# STM32C031 register map
File version: 1.4
CPU: CM0 r0p0, little endian, MPU, FPU, 4 interrupt priority bits
Registers are 32-bit, read-write, reset 0x0 unless marked. A register's access mark holds for its fields unless they carry their own. Offsets are from the block's base; [hi:lo] are bit positions.

## RTC — RTC register block
Base 0x40002800
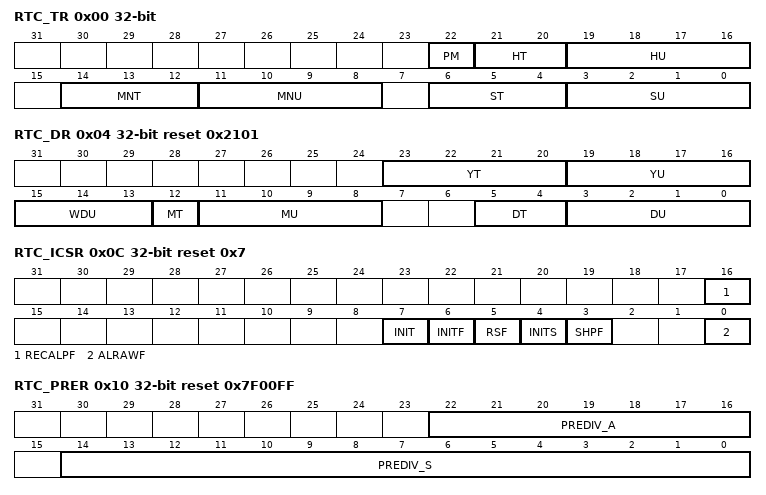
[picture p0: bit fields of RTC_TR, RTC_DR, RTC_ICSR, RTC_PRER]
0x00 RTC_TR — RTC time register
  [22] PM — AM/PM notation
    0=AM or 24-hour format; 1=PM
  [21:20] HT — Hour tens in BCD format
  [19:16] HU — Hour units in BCD format
  [14:12] MNT — Minute tens in BCD format
  [11:8] MNU — Minute units in BCD format
  [6:4] ST — Second tens in BCD format
  [3:0] SU — Second units in BCD format
0x04 RTC_DR reset 0x2101 — RTC date register
  [23:20] YT — Year tens in BCD format
  [19:16] YU — Year units in BCD format
  [15:13] WDU — Week day units ...
    0=forbidden; 1=Monday; 7=Sunday
  [12] MT — Month tens in BCD format
  [11:8] MU — Month units in BCD format
  [5:4] DT — Date tens in BCD format
  [3:0] DU — Date units in BCD format
0x08 RTC_SSR ro — RTC sub second register
  [15:0] SS — Sub second value SS[15:0] is the value in the synchronous prescaler counter. The fraction of a second is given by the formula below: Second fraction = (PREDIV_S - SS) / (PREDIV_S + 1) Note: SS can be larger than PREDIV_S only after a shift operation. In that case, the correct time/date is one second less than as indicated by RTC_TR/RTC_DR.
0x0C RTC_ICSR access per field reset 0x7 — RTC initialization control and status register
  [16] RECALPF ro — Recalibration pending Flag The RECALPF status flag is automatically set to 1 when software writes to the RTC_CALR register, indicating that the RTC_CALR register is blocked. When the new calibration settings are taken into account, this bit returns to 0. Refer to .
  [7] INIT rw — Initialization mode
    0=Free running mode; 1=Initialization mode used to program time and date register (RTC_TR and RTC_DR), and prescaler register (RTC_PRER). Counters are stopped and start counting from the new value when INIT is reset.
  [6] INITF ro — Initialization flag When this bit is set to 1, the RTC is in initialization state, and the time, date and prescaler registers can be updated.
    0=Calendar registers update is not allowed; 1=Calendar registers update is allowed
  [5] RSF rw — Registers synchronization flag This bit is set by hardware each time the calendar registers are copied into the shadow registers (RTC_SSR, RTC_TR and RTC_DR). This bit is cleared by hardware in initialization mode, while a shift operation is pending (SHPF = 1), or when in bypass shadow register mode (BYPSHAD = 1). This bit can also be cleared by software. It is cleared either by software or by hardware in initialization mode.
    0=Calendar shadow registers not yet synchronized; 1=Calendar shadow registers synchronized
  [4] INITS ro — Initialization status flag This bit is set by hardware when the calendar year field is different from 0 (Power-on reset state).
    0=Calendar has not been initialized; 1=Calendar has been initialized
  [3] SHPF ro — Shift operation pending This flag is set by hardware as soon as a shift operation is initiated by a write to the RTC_SHIFTR register. It is cleared by hardware when the corresponding shift operation has been executed. Writing to the SHPF bit has no effect.
    0=No shift operation is pending; 1=A shift operation is pending
  [0] ALRAWF ro — Alarm A write flag This bit is set by hardware when alarm A values can be changed, after the ALRAE bit has been set to 0 in RTC_CR. It is cleared by hardware in initialization mode.
    0=Alarm A update not allowed; 1=Alarm A update allowed
0x10 RTC_PRER reset 0x7F00FF — RTC prescaler register
  [22:16] PREDIV_A — Asynchronous prescaler factor This is the asynchronous division factor: ck_apre frequency = RTCCLK frequency/(PREDIV_A+1)
  [14:0] PREDIV_S — Synchronous prescaler factor This is the synchronous division factor: ck_spre frequency = ck_apre frequency/(PREDIV_S+1)
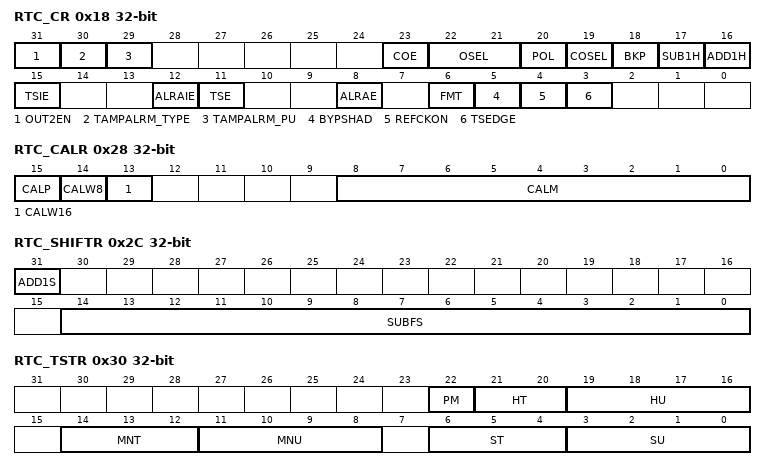
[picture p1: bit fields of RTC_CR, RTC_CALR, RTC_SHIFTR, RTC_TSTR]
0x18 RTC_CR access per field — RTC control register
  [31] OUT2EN rw — RTC_OUT2 output enable Setting this bit allows to remap the RTC outputs on RTC_OUT2 as follows: OUT2EN = 0: RTC output 2 disable If OSEL different of 00 or TAMPOE = 1: TAMPALRM is output on RTC_OUT1 If OSEL = 00 and TAMPOE = 0 and COE = 1: CALIB is output on RTC_OUT1 OUT2EN = 1: RTC output 2 enable If (OSEL different of 00 or TAMPOE = 1) and COE = 0: TAMPALRM is output on RTC_OUT2 If OSEL = 00 and TAMPOE = 0 and COE = 1: CALIB is output on RTC_OUT2 If (OSELdifferent of 00 or TAMPOE = 1) and COE = 1: CALIB is output on RTC_OUT2 and TAMPALRM is output on RTC_OUT1.
  [30] TAMPALRM_TYPE rw — TAMPALRM output type
    0=TAMPALRM is push-pull output; 1=TAMPALRM is open-drain output
  [29] TAMPALRM_PU rw — TAMPALRM pull-up enable
    0=No pull-up is applied on TAMPALRM output; 1=A pull-up is applied on TAMPALRM output
  [23] COE rw — Calibration output enable This bit enables the CALIB output
    0=Calibration output disabled; 1=Calibration output enabled
  [22:21] OSEL rw — Output selection These bits are used to select the flag to be routed to TAMPALRM output.
    0=Output disabled; 1=Alarm A output enabled
  [20] POL rw — Output polarity This bit is used to configure the polarity of TAMPALRM output.
    0=The pin is high when ALRAF is asserted (depending on OSEL[1:0]); 1=The pin is low when ALRAF is asserted (depending on OSEL[1:0])
  [19] COSEL rw — Calibration output selection When COE = 1, this bit selects which signal is output on CALIB. These frequencies are valid for RTCCLK at 32.768 kHz and prescalers at their default values (PREDIV_A = 127 and PREDIV_S = 255). Refer to .
    0=Calibration output is 512 Hz; 1=Calibration output is 1 Hz
  [18] BKP rw — Backup This bit can be written by the user to memorize whether the daylight saving time change has been performed or not.
  [17] SUB1H wo — Subtract 1 hour (winter time change) When this bit is set outside initialization mode, 1 hour is subtracted to the calendar time if the current hour is not 0. This bit is always read as 0. Setting this bit has no effect when current hour is 0.
    0=No effect; 1=Subtracts 1 hour to the current time. This can be used for winter time change.
  [16] ADD1H wo — Add 1 hour (summer time change) When this bit is set outside initialization mode, 1 hour is added to the calendar time. This bit is always read as 0.
    0=No effect; 1=Adds 1 hour to the current time. This can be used for summer time change
  [15] TSIE rw — Timestamp interrupt enable
    0=Timestamp interrupt disable; 1=Timestamp interrupt enable
  [12] ALRAIE rw — Alarm A interrupt enable
    0=Alarm A interrupt disabled; 1=Alarm A interrupt enabled
  [11] TSE rw — timestamp enable
    0=timestamp disable; 1=timestamp enable
  [8] ALRAE rw — Alarm A enable
    0=Alarm A disabled; 1=Alarm A enabled
  [6] FMT rw — Hour format
    0=24 hour/day format; 1=AM/PM hour format
  [5] BYPSHAD rw — Bypass the shadow registers Note: If the frequency of the APB1 clock is less than seven times the frequency of RTCCLK, BYPSHAD must be set to 1.
    0=Calendar values (when reading from RTC_SSR, RTC_TR, and RTC_DR) are taken from the shadow registers, which are updated once every two RTCCLK cycles; 1=Calendar values (when reading from RTC_SSR, RTC_TR, and RTC_DR) are taken directly from the calendar counters
  [4] REFCKON rw — RTC_REFIN reference clock detection enable (50 or 60 Hz) Note: PREDIV_S must be 0x00FF.
    0=RTC_REFIN detection disabled; 1=RTC_REFIN detection enabled
  [3] TSEDGE rw — Timestamp event active edge TSE must be reset when TSEDGE is changed to avoid unwanted TSF setting.
    0=RTC_TS input rising edge generates a timestamp event; 1=RTC_TS input falling edge generates a timestamp event
0x24 RTC_WPR wo — RTC write protection register
  [7:0] KEY — Write protection key This byte is written by software. Reading this byte always returns 0x00. Refer to for a description of how to unlock RTC register write protection.
0x28 RTC_CALR — RTC calibration register
  [15] CALP — Increase frequency of RTC by 488.5 ppm This feature is intended to be used in conjunction with CALM, which lowers the frequency of the calendar with a fine resolution. if the input frequency is 32768 Hz, the number of RTCCLK pulses added during a 32-second window is calculated as follows: (512 CALP) - CALM. Refer to .
    0=No RTCCLK pulses are added; 1=One RTCCLK pulse is effectively inserted every 211 pulses (frequency increased by 488.5 ppm)
  [14] CALW8 — Use an 8-second calibration cycle period When CALW8 is set to 1, the 8-second calibration cycle period is selected. Note: CALM[1:0] are stuck at 00 when CALW8 = 1. Refer to digital calibration.
  [13] CALW16 — Use a 16-second calibration cycle period When CALW16 is set to 1, the 16-second calibration cycle period is selected. This bit must not be set to 1 if CALW8 = 1. Note: CALM[0] is stuck at 0 when CALW16 = 1. Refer to calibration.
  [8:0] CALM — Calibration minus The frequency of the calendar is reduced by masking CALM out of 220 RTCCLK pulses (32 seconds if the input frequency is 32768 Hz). This decreases the frequency of the calendar with a resolution of 0.9537 ppm. To increase the frequency of the calendar, this feature should be used in conjunction with CALP. See .
0x2C RTC_SHIFTR wo — RTC shift control register
  [31] ADD1S — Add one second This bit is write only and is always read as zero. Writing to this bit has no effect when a shift operation is pending (when SHPF = 1, in RTC_ICSR). This function is intended to be used with SUBFS (see description below) in order to effectively add a fraction of a second to the clock in an atomic operation.
    0=No effect; 1=Add one second to the clock/calendar
  [14:0] SUBFS — Subtract a fraction of a second These bits are write only and is always read as zero. Writing to this bit has no effect when a shift operation is pending (when SHPF = 1, in RTC_ICSR). The value which is written to SUBFS is added to the synchronous prescaler counter. Since this counter counts down, this operation effectively subtracts from (delays) the clock by: Delay (seconds) = SUBFS / (PREDIV_S + 1) A fraction of a second can effectively be added to the clock (advancing the clock) when the ADD1S function is used in conjunction with SUBFS, effectively advancing the clock by: Advance (seconds) = (1 - (SUBFS / (PREDIV_S + 1))). Note: Writing to SUBFS causes RSF to be cleared. Software can then wait until RSF = 1 to be sure that the shadow registers have been updated with the shifted time.
0x30 RTC_TSTR ro — RTC timestamp time register
  [22] PM — AM/PM notation
    0=AM or 24-hour format; 1=PM
  [21:20] HT — Hour tens in BCD format.
  [19:16] HU — Hour units in BCD format.
  [14:12] MNT — Minute tens in BCD format.
  [11:8] MNU — Minute units in BCD format.
  [6:4] ST — Second tens in BCD format.
  [3:0] SU — Second units in BCD format.
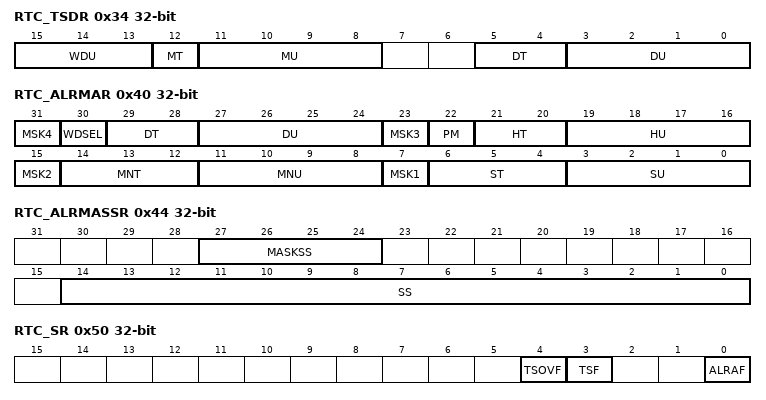
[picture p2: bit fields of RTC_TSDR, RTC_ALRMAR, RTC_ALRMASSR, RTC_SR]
0x34 RTC_TSDR ro — RTC timestamp date register
  [15:13] WDU — Week day units
  [12] MT — Month tens in BCD format
  [11:8] MU — Month units in BCD format
  [5:4] DT — Date tens in BCD format
  [3:0] DU — Date units in BCD format
0x38 RTC_TSSSR ro — RTC timestamp sub second register
  [15:0] SS — Sub second value SS[15:0] is the value of the synchronous prescaler counter when the timestamp event occurred.
0x40 RTC_ALRMAR — RTC alarm A register
  [31] MSK4 — Alarm A date mask
    0=Alarm A set if the date/day match; 1=Date/day dont care in alarm A comparison
  [30] WDSEL — Week day selection
    0=DU[3:0] represents the date units; 1=DU[3:0] represents the week day. DT[1:0] is dont care.
  [29:28] DT — Date tens in BCD format
  [27:24] DU — Date units or day in BCD format
  [23] MSK3 — Alarm A hours mask
    0=Alarm A set if the hours match; 1=Hours dont care in alarm A comparison
  [22] PM — AM/PM notation
    0=AM or 24-hour format; 1=PM
  [21:20] HT — Hour tens in BCD format
  [19:16] HU — Hour units in BCD format
  [15] MSK2 — Alarm A minutes mask
    0=Alarm A set if the minutes match; 1=Minutes dont care in alarm A comparison
  [14:12] MNT — Minute tens in BCD format
  [11:8] MNU — Minute units in BCD format
  [7] MSK1 — Alarm A seconds mask
    0=Alarm A set if the seconds match; 1=Seconds dont care in alarm A comparison
  [6:4] ST — Second tens in BCD format.
  [3:0] SU — Second units in BCD format.
0x44 RTC_ALRMASSR — RTC alarm A sub second register
  [27:24] MASKSS — Mask the most-significant bits starting at this bit 2: SS[14:2] are dont care in alarm A comparison. Only SS[1:0] are compared. 3: SS[14:3] are dont care in alarm A comparison. Only SS[2:0] are compared. ... 12: SS[14:12] are dont care in alarm A comparison. SS[11:0] are compared. 13: SS[14:13] are dont care in alarm A comparison. SS[12:0] are compared. 14: SS[14] is dont care in alarm A comparison. SS[13:0] are compared. 15: All 15 SS bits are compared and must match to activate alarm. The overflow bits of the synchronous counter (bits 15) is never compared. This bit can be different from 0 only after a shift operation. Note: The overflow bits of the synchronous counter (bits 15) is never compared. This bit can be different from 0 only after a shift operation.
    0=No comparison on sub seconds for alarm A. The alarm is set when the seconds unit is incremented (assuming that the rest of the fields match).; 1=SS[14:1] are dont care in alarm A comparison. Only SS[0] is compared.
  [14:0] SS — Sub seconds value This value is compared with the contents of the synchronous prescaler counter to determine if alarm A is to be activated. Only bits 0 up MASKSS-1 are compared.
0x50 RTC_SR ro — RTC status register
  [4] TSOVF — Timestamp overflow flag This flag is set by hardware when a timestamp event occurs while TSF is already set. It is recommended to check and then clear TSOVF only after clearing the TSF bit. Otherwise, an overflow might not be noticed if a timestamp event occurs immediately before the TSF bit is cleared.
  [3] TSF — Timestamp flag This flag is set by hardware when a timestamp event occurs.
  [0] ALRAF — Alarm A flag This flag is set by hardware when the time/date registers (RTC_TR and RTC_DR) match the alarm A register (RTC_ALRMAR).
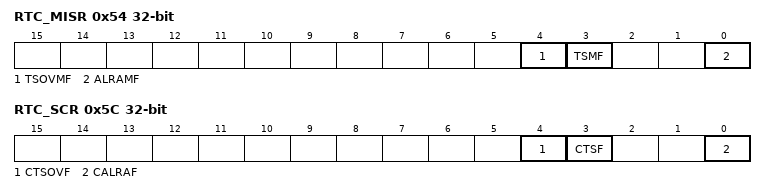
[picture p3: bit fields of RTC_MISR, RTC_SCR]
0x54 RTC_MISR ro — RTC masked interrupt status register
  [4] TSOVMF — Timestamp overflow masked flag This flag is set by hardware when a timestamp interrupt occurs while TSMF is already set. It is recommended to check and then clear TSOVF only after clearing the TSF bit. Otherwise, an overflow might not be noticed if a timestamp event occurs immediately before the TSF bit is cleared.
  [3] TSMF — Timestamp masked flag This flag is set by hardware when a timestamp interrupt occurs.
  [0] ALRAMF — Alarm A masked flag This flag is set by hardware when the alarm A interrupt occurs.
0x5C RTC_SCR wo — RTC status clear register
  [4] CTSOVF — Clear timestamp overflow flag Writing 1 in this bit clears the TSOVF bit in the RTC_SR register. It is recommended to check and then clear TSOVF only after clearing the TSF bit. Otherwise, an overflow might not be noticed if a timestamp event occurs immediately before the TSF bit is cleared.
  [3] CTSF — Clear timestamp flag Writing 1 in this bit clears the TSOVF bit in the RTC_SR register.
  [0] CALRAF — Clear alarm A flag Writing 1 in this bit clears the ALRAF bit in the RTC_SR register.
